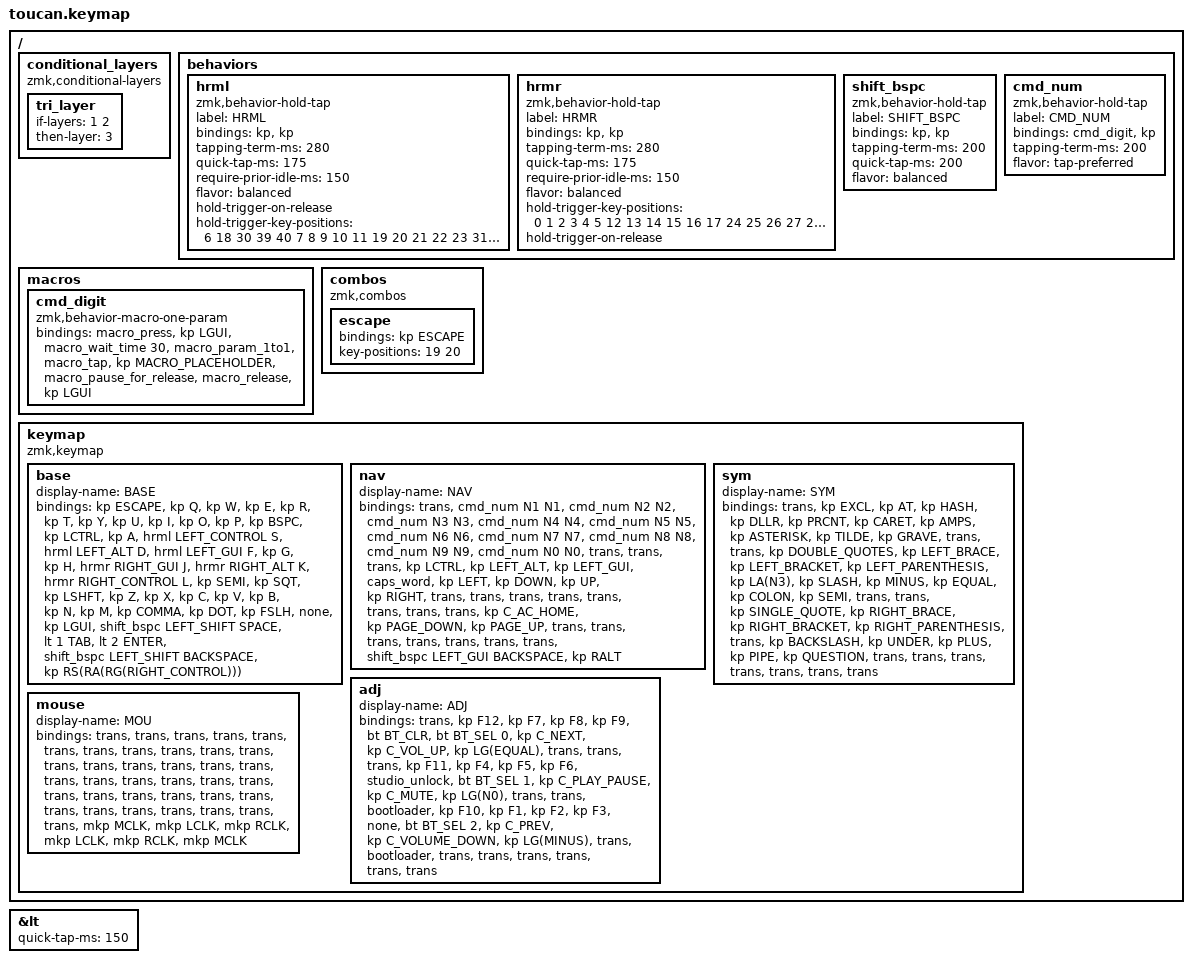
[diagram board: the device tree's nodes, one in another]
#include <behaviors.dtsi>
#include <dt-bindings/zmk/bt.h>
#include <dt-bindings/zmk/keys.h>
#include <dt-bindings/zmk/pointing.h>

#define BASE 0
#define NAV  1
#define SYM  2
#define ADJ  3
#define MOU  4

&lt { quick-tap-ms = <150>; };

/ {
    conditional_layers {
        compatible = "zmk,conditional-layers";

        tri_layer {
            if-layers = <1 2>;
            then-layer = <3>;
        };
    };

    behaviors {
        hrml: hrml {
            compatible = "zmk,behavior-hold-tap";
            label = "HRML";
            bindings = <&kp>, <&kp>;

            #binding-cells = <2>;
            tapping-term-ms = <280>;
            quick-tap-ms = <175>;
            require-prior-idle-ms = <150>;
            flavor = "balanced";
            hold-trigger-on-release;
            hold-trigger-key-positions = <6 18 30 39 40 7 8 9 10 11 19 20 21 22 23 31 32 33 34 35 41 38 37 36>;
        };

        hrmr: hrmr {
            compatible = "zmk,behavior-hold-tap";
            label = "HRMR";
            bindings = <&kp>, <&kp>;

            #binding-cells = <2>;
            tapping-term-ms = <280>;
            quick-tap-ms = <175>;
            require-prior-idle-ms = <150>;
            flavor = "balanced";
            hold-trigger-key-positions = <0 1 2 3 4 5 12 13 14 15 16 17 24 25 26 27 28 29 36 37 38 39 40 41>;
            hold-trigger-on-release;
        };

        // Right inner thumb: hold for shift, tap for delete. On nav the same key holds
        // for Cmd instead, so Cmd+number stays reachable without losing delete.
        //
        // No hold-trigger-key-positions: shift has to reach every position, including
        // right-hand letters on this same hand, so positional gating would only break
        // legitimate capitals. No require-prior-idle-ms either: shift is pressed mid
        // typing flow, so a typing-streak guard would delete a character exactly when a
        // capital was wanted. Both of those guards are right for hrml/hrmr and wrong here.
        //
        // quick-tap-ms is what restores held-delete: a re-press inside the window forces
        // the tap branch, and a hold-tap's tap keycode stays down until release, so the
        // host autorepeats it. Tap delete, then press and hold again to repeat.

        shift_bspc: shift_bspc {
            compatible = "zmk,behavior-hold-tap";
            label = "SHIFT_BSPC";
            bindings = <&kp>, <&kp>;

            #binding-cells = <2>;
            tapping-term-ms = <200>;
            quick-tap-ms = <200>;
            flavor = "balanced";
        };

        // Nav number row: tap for the digit, hold for Cmd+digit. Cmd+number needs no
        // third key held, just the nav thumb and one finger, same as typing the digit.
        //
        // tap-preferred so only time decides: digits are typed in fast runs, and a
        // roll onto the next digit must never turn the previous one into Cmd+digit.

        cmd_num: cmd_num {
            compatible = "zmk,behavior-hold-tap";
            label = "CMD_NUM";
            bindings = <&cmd_digit>, <&kp>;

            #binding-cells = <2>;
            tapping-term-ms = <200>;
            flavor = "tap-preferred";
        };
    };

    macros {
        // Hold half of cmd_num. Sending LG(N1) puts Cmd and the digit in one HID
        // report, and macOS apps (T3 Code, Slack) then saw Cmd but dropped the
        // digit: their Cmd-hold labels appeared and the jump never fired. Pressing
        // Cmd first and tapping the digit a moment later matches a real keyboard.
        // Cmd stays down until the key is released.

        cmd_digit: cmd_digit {
            compatible = "zmk,behavior-macro-one-param";
            #binding-cells = <1>;
            bindings
                = <&macro_press &kp LGUI>
                , <&macro_wait_time 30>
                , <&macro_param_1to1>
                , <&macro_tap &kp MACRO_PLACEHOLDER>
                , <&macro_pause_for_release>
                , <&macro_release &kp LGUI>
                ;
        };
    };

    combos {
        compatible = "zmk,combos";

        escape {
            bindings = <&kp ESCAPE>;
            key-positions = <19 20>;
        };
    };

    keymap {
        compatible = "zmk,keymap";

        base {
            display-name = "BASE";
            bindings = <
&kp ESCAPE  &kp Q  &kp W  &kp E  &kp R  &kp T  &kp Y  &kp U  &kp I  &kp O  &kp P  &kp BSPC  &kp LCTRL  &kp A  &hrml LEFT_CONTROL S  &hrml LEFT_ALT D  &hrml LEFT_GUI F  &kp G  &kp H  &hrmr RIGHT_GUI J  &hrmr RIGHT_ALT K  &hrmr RIGHT_CONTROL L  &kp SEMI  &kp SQT  &kp LSHFT  &kp Z  &kp X  &kp C  &kp V  &kp B  &kp N  &kp M  &kp COMMA  &kp DOT  &kp FSLH  &none  &kp LGUI  &shift_bspc LEFT_SHIFT SPACE  &lt 1 TAB  &lt 2 ENTER  &shift_bspc LEFT_SHIFT BACKSPACE  &kp RS(RA(RG(RIGHT_CONTROL)))
            >;
        };

        nav {
            display-name = "NAV";
            bindings = <
&trans  &cmd_num N1 N1  &cmd_num N2 N2  &cmd_num N3 N3  &cmd_num N4 N4  &cmd_num N5 N5  &cmd_num N6 N6  &cmd_num N7 N7  &cmd_num N8 N8  &cmd_num N9 N9  &cmd_num N0 N0  &trans  &trans  &trans  &kp LCTRL  &kp LEFT_ALT  &kp LEFT_GUI  &caps_word  &kp LEFT  &kp DOWN  &kp UP  &kp RIGHT  &trans  &trans  &trans  &trans  &trans  &trans  &trans  &trans  &kp C_AC_HOME  &kp PAGE_DOWN  &kp PAGE_UP  &trans  &trans  &trans  &trans  &trans  &trans  &trans  &shift_bspc LEFT_GUI BACKSPACE  &kp RALT
            >;
        };

        sym {
            display-name = "SYM";
            bindings = <
&trans  &kp EXCL  &kp AT  &kp HASH  &kp DLLR  &kp PRCNT  &kp CARET  &kp AMPS  &kp ASTERISK  &kp TILDE  &kp GRAVE  &trans  &trans  &kp DOUBLE_QUOTES  &kp LEFT_BRACE  &kp LEFT_BRACKET  &kp LEFT_PARENTHESIS  &kp LA(N3)  &kp SLASH  &kp MINUS  &kp EQUAL  &kp COLON  &kp SEMI  &trans  &trans  &kp SINGLE_QUOTE  &kp RIGHT_BRACE  &kp RIGHT_BRACKET  &kp RIGHT_PARENTHESIS  &trans  &kp BACKSLASH  &kp UNDER  &kp PLUS  &kp PIPE  &kp QUESTION  &trans  &trans  &trans  &trans  &trans  &trans  &trans
            >;
        };

        adj {
            display-name = "ADJ";
            bindings = <
&trans  &kp F12  &kp F7  &kp F8  &kp F9  &bt BT_CLR  &bt BT_SEL 0  &kp C_NEXT  &kp C_VOL_UP  &kp LG(EQUAL)  &trans  &trans  &trans  &kp F11  &kp F4  &kp F5  &kp F6  &studio_unlock  &bt BT_SEL 1  &kp C_PLAY_PAUSE  &kp C_MUTE  &kp LG(N0)  &trans  &trans  &bootloader  &kp F10  &kp F1  &kp F2  &kp F3  &none  &bt BT_SEL 2  &kp C_PREV  &kp C_VOLUME_DOWN  &kp LG(MINUS)  &trans  &bootloader  &trans  &trans  &trans  &trans  &trans  &trans
            >;
        };

        // Momentarily active while a finger is on the trackpad (see is_touching_processor
        // in toucan.dtsi). Turns the thumb keys into mouse buttons so you can click without
        // lifting off the pad. All other keys pass through to the layer below.

        mouse {
            display-name = "MOU";
            bindings = <
&trans  &trans  &trans  &trans  &trans  &trans  &trans  &trans  &trans  &trans  &trans  &trans  &trans  &trans  &trans  &trans  &trans  &trans  &trans  &trans  &trans  &trans  &trans  &trans  &trans  &trans  &trans  &trans  &trans  &trans  &trans  &trans  &trans  &trans  &trans  &trans  &mkp MCLK  &mkp LCLK  &mkp RCLK  &mkp LCLK  &mkp RCLK  &mkp MCLK
            >;
        };
    };
};
